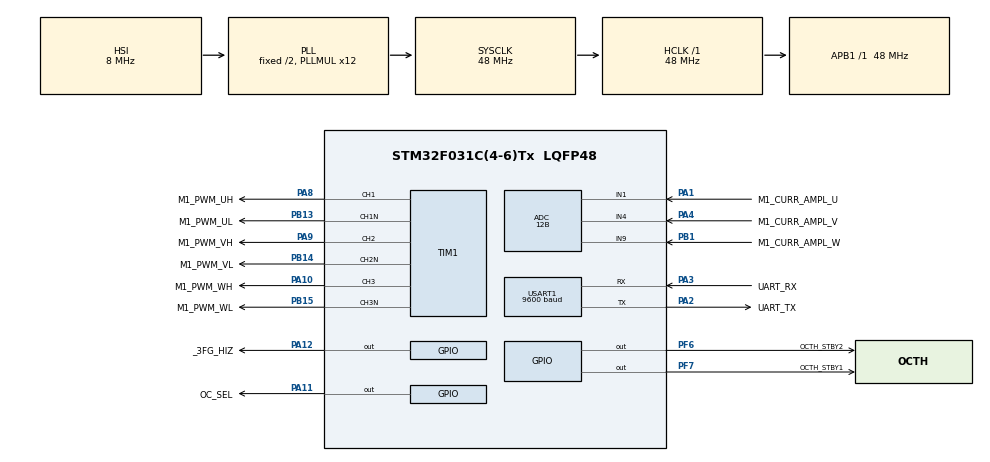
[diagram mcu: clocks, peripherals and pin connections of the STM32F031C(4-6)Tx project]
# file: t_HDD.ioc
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ADC.ClockPrescaler=ADC_CLOCK_ASYNC_DIV1
ADC.ContinuousConvMode=DISABLE
ADC.DMAContinuousRequests=ENABLE
ADC.DataAlign=ADC_DATAALIGN_LEFT
ADC.DiscontinuousConvMode=DISABLE
ADC.EOCSelection=ADC_EOC_SINGLE_CONV
ADC.EnableAnalogWatchDog=false
ADC.ExternalTrigConv=ADC_EXTERNALTRIGCONV_T1_TRGO
ADC.ExternalTrigConvEdge=ADC_EXTERNALTRIGCONVEDGE_RISING
ADC.LowPowerAutoPowerOff=DISABLE
ADC.LowPowerAutoWait=DISABLE
ADC.Overrun=ADC_OVR_DATA_PRESERVED
ADC.Resolution=ADC_RESOLUTION_12B
ADC.SamplingTime=ADC_SAMPLETIME_7CYCLES_5
ADC.ScanConvMode=ADC_SCAN_DIRECTION_FORWARD
Dma.ADC.0.Direction=DMA_PERIPH_TO_MEMORY
Dma.ADC.0.Instance=DMA1_Channel1
Dma.ADC.0.MemDataAlignment=DMA_MDATAALIGN_HALFWORD
Dma.ADC.0.MemInc=DMA_MINC_ENABLE
Dma.ADC.0.Mode=DMA_CIRCULAR
Dma.ADC.0.PeriphDataAlignment=DMA_PDATAALIGN_HALFWORD
Dma.ADC.0.PeriphInc=DMA_PINC_DISABLE
Dma.ADC.0.Priority=DMA_PRIORITY_HIGH
Dma.Request0=ADC
ExtraMW=MotorControl
ExtraMW.MotorControl.Config=MotorControl
ExtraMW.MotorControl.Mode=MotorControl
ExtraMW.MotorControl.Root=MCSDK_v5.1.3/MotorControl
ExtraMW.MotorControl.Template=templates
Mcu.Family=STM32F0
Mcu.Name=STM32F031C(4-6)Tx
Mcu.Package=LQFP48
MotorControl.ADC_1_PERIPH=ADC1
MotorControl.ADC_2_PERIPH=ADC2
MotorControl.ADC_AHBPERIPH=RCC_AHBPeriph_ADC12
MotorControl.ADC_CLOCK_WB_DIV=0
MotorControl.ADC_CLOCK_WB_FREQ=14
MotorControl.ADC_PERIPH=ADC1
MotorControl.ALIGNMENT_ANGLE_DEG=0
MotorControl.ALIGNMENT_DURATION=700
MotorControl.AMPLIFICATION_GAIN=10.00
MotorControl.ANGC={0,0,0,0,0,0,0,0}
MotorControl.BEMF_CONSISTENCY_GAIN=45
MotorControl.BEMF_CONSISTENCY_TOL=45
MotorControl.BKIN1_FILTER=0
MotorControl.BKIN2_FILTER=0
MotorControl.BKIN2_MODE=NONE
MotorControl.BKIN_MODE=NONE
MotorControl.BOARD=CUSTOM
MotorControl.BRKIN2_GPIO_AF=GPIO_AF_2
MotorControl.BRKIN_GPIO_AF=GPIO_AF_2
MotorControl.BUS_VOLTAGE_READING=false
MotorControl.CLOCK_FREQUENCY=CPU_CLK_48_MHZ
MotorControl.CLOCK_SOURCE=INTERNAL
MotorControl.CONSTANT1_D=2136
MotorControl.CONSTANT1_Q=2136
MotorControl.CONSTANT2_QD=315
MotorControl.CORD_BEMF_CONSISTENCY_GAIN=64
MotorControl.CORD_BEMF_CONSISTENCY_TOL=64
MotorControl.CORD_F1=512
MotorControl.CORD_F2=16384
MotorControl.CORD_FIFO_DEPTH_01HZ=64
MotorControl.CORD_FIFO_DEPTH_DPP=64
MotorControl.CORD_GAIN1=-468
MotorControl.CORD_GAIN2=8762
MotorControl.CORD_MAX_ACCEL_DPPP=241
MotorControl.CORD_MEAS_ERRORS_BEFORE_FAULTS=3
MotorControl.CORD_VARIANCE_THRESHOLD=4
MotorControl.CPU_CLK_48_MHZ=true
MotorControl.CTRBDID=0
MotorControl.CURRENT_READING_TOPOLOGY=THREE_SHUNT
MotorControl.CURR_SAMPLING_TIME=7
MotorControl.DAC_EMULATED=false
MotorControl.DAC_FUNCTIONALITY=false
MotorControl.DAC_TIMER_CH1_GPIO_PIN=LL_GPIO_PIN_0
MotorControl.DAC_TIMER_CH1_GPIO_PORT=GPIOA
MotorControl.DAC_TIMER_CH2_GPIO_PIN=LL_GPIO_PIN_0
MotorControl.DAC_TIMER_CH2_GPIO_PORT=GPIOA
MotorControl.DAC_TIMER_REMAPPING=NO_REMAP
MotorControl.DAC_TIMER_SELECTION=TIM3
MotorControl.DC_CURRENT_RS_MEAS=0.50
MotorControl.DEBUG_DAC_CH1=false
MotorControl.DEBUG_DAC_CH2=false
MotorControl.DEFAULT_CONTROL_MODE=STC_SPEED_MODE
MotorControl.DEFAULT_DAC_CHANNEL_1=MC_PROTOCOL_REG_I_A
MotorControl.DEFAULT_DAC_CHANNEL_2=MC_PROTOCOL_REG_I_B
MotorControl.DEFAULT_DAC_MOTOR=0
MotorControl.DEFAULT_FLUX_COMPONENT=0
MotorControl.DEFAULT_TARGET_SPEED_RPM=6000
MotorControl.DEFAULT_TORQUE_COMPONENT=11915
MotorControl.DISSIPATIVE_BRAKE_POLARITY=DOUT_ACTIVE_HIGH
MotorControl.DRIVES_NUMBER_SELECTION=SINGLEDRIVE
MotorControl.EMERGENCY2_STOP_GPIO_PIN=LL_GPIO_PIN_12
MotorControl.EMERGENCY2_STOP_GPIO_PORT=GPIOB
MotorControl.EMERGENCY_STOP_GPIO_PIN=LL_GPIO_PIN_12
MotorControl.EMERGENCY_STOP_GPIO_PORT=GPIOB
MotorControl.ENABLE_SL_ALGO_FROM_PHASE=1
MotorControl.ENCODER_AVAILABLE=false
MotorControl.ENCODER_PPR=1250
MotorControl.ENC_AVERAGING_FIFO_DEPTH=16
MotorControl.ENC_A_GPIO_PIN=LL_GPIO_PIN_6
MotorControl.ENC_A_GPIO_PORT=GPIOA
MotorControl.ENC_B_GPIO_PIN=LL_GPIO_PIN_7
MotorControl.ENC_B_GPIO_PORT=GPIOA
MotorControl.ENC_ICx_FILTER=34
MotorControl.ENC_INVERT_SPEED=false
MotorControl.ENC_MEAS_ERRORS_BEFORE_FAULTS=3
MotorControl.ENC_TIMER_REMAPPING=NO_REMAP_TIM3
MotorControl.ENC_TIMER_SELECTION=ENC_TIM3
MotorControl.EXT_CLOCK_FREQUENCY=INT_RC_OSC
MotorControl.F1=512
MotorControl.F2=16384
MotorControl.FEEDBACK_NET_FILTERING=false
MotorControl.FEED_FORWARD_CURRENT_REG_ENABLING=false
MotorControl.FINAL_I_ALIGNMENT=19858
MotorControl.FLUX_WEAKENING_ENABLING=false
MotorControl.FW_KIDIV=32768
MotorControl.FW_KI_GAIN=5000
MotorControl.FW_KPDIV=32768
MotorControl.FW_KP_GAIN=3000
MotorControl.FW_VOLTAGE_REF=985
MotorControl.GAIN1=-468
MotorControl.GAIN2=8762
MotorControl.H1_GPIO_PIN=LL_GPIO_PIN_0
MotorControl.H1_GPIO_PORT=GPIOA
MotorControl.H2_GPIO_PIN=LL_GPIO_PIN_1
MotorControl.H2_GPIO_PORT=GPIOA
MotorControl.H3_GPIO_PIN=LL_GPIO_PIN_2
MotorControl.H3_GPIO_PORT=GPIOA
MotorControl.HALL_AVERAGING_FIFO_DEPTH=6
MotorControl.HALL_ICx_FILTER=62
MotorControl.HALL_MEAS_ERRORS_BEFORE_FAULTS=3
MotorControl.HALL_PHASE_SHIFT=300
MotorControl.HALL_SENSORS_AVAILABLE=false
MotorControl.HALL_SENSORS_PLACEMENT=DEGREES_120
MotorControl.HALL_TIMER_REMAPPING=NO_REMAP_TIM2
MotorControl.HALL_TIMER_SELECTION=HALL_TIM2
MotorControl.HFI_AMPLITUDE=25
MotorControl.HFI_DC_0_COEFF=0.00146
MotorControl.HFI_DC_1_COEFF=0.002921
MotorControl.HFI_DC_2_COEFF=0.00146
MotorControl.HFI_DC_3_COEFF=1.889033
MotorControl.HFI_DC_4_COEFF=-0.894874
MotorControl.HFI_DEBUG_MODE=false
MotorControl.HFI_FREQUENCY=400
MotorControl.HFI_HIFRAMPLSCAN=25
MotorControl.HFI_HP_ID_0_COEFF=0.855931
MotorControl.HFI_HP_ID_1_COEFF=-1.711861
MotorControl.HFI_HP_ID_2_COEFF=0.855931
MotorControl.HFI_HP_ID_3_COEFF=1.690996
MotorControl.HFI_HP_ID_4_COEFF=-0.732726
MotorControl.HFI_IDH_DELAY=32400
MotorControl.HFI_LOCKFREQ=82
MotorControl.HFI_LP_ID_0_COEFF=0.032106
MotorControl.HFI_LP_ID_1_COEFF=0.064213
MotorControl.HFI_LP_ID_2_COEFF=0.032106
MotorControl.HFI_LP_ID_3_COEFF=1.433067
MotorControl.HFI_LP_ID_4_COEFF=-0.561492
MotorControl.HFI_MAXANGLEDIFF=3640
MotorControl.HFI_MINIMUM_SPEED_RPM=402
MotorControl.HFI_NOTCH_IQD_0_COEFF=0.928286
MotorControl.HFI_NOTCH_IQD_1_COEFF=-1.765705
MotorControl.HFI_NOTCH_IQD_2_COEFF=0.928286
MotorControl.HFI_NOTCH_IQD_3_COEFF=1.765705
MotorControl.HFI_NOTCH_IQD_4_COEFF=-0.856572
MotorControl.HFI_NSDETPOINTSSKIP=10
MotorControl.HFI_NSMAXDETPOINTS=20
MotorControl.HFI_NS_MIN_SAT_DIFF=0
MotorControl.HFI_PID_KIDIV=32768
MotorControl.HFI_PID_KI_DEFAULT=400
MotorControl.HFI_PID_KPDIV=16384
MotorControl.HFI_PID_KP_DEFAULT=800
MotorControl.HFI_PLL_KI_DEFAULT=0.00400
MotorControl.HFI_PLL_KP_DEFAULT=0.00060
MotorControl.HFI_RESTARTTIMESEC=0.1
MotorControl.HFI_RESTART_RPM_TH=(((HFI_STO_RPM_TH)+(STO_HFI_RPM_TH))/2)
MotorControl.HFI_REVERT_DIRECTION=true
MotorControl.HFI_SCANROTATIONSNO=3
MotorControl.HFI_SPD_BUFFER_DEPTH_01HZ=32
MotorControl.HFI_STEPANGLE=3640
MotorControl.HFI_STO_RPM_TH=OBS_MINIMUM_SPEED_RPM
MotorControl.HFI_WAITAFTERNS2=4
MotorControl.HFI_WAITBEFORESN=6
MotorControl.HFI_WAITSYNCH=20
MotorControl.HFI_WAITTRACK=20
MotorControl.HIGH_SIDE_BRAKE_STATE=false
MotorControl.HIGH_SIDE_IDLE_STATE=false
MotorControl.HW_COMPLEMENTED_LOW_SIDE=false
MotorControl.HW_DEAD_TIME_NS=900
MotorControl.HW_OV_CURRENT_PROT_BYPASS=false
MotorControl.ID_DEMAG=-9929
MotorControl.INRUSH_CURRLIMIT_AT_POWER_ON=true
MotorControl.INRUSH_CURRLIMIT_CHANGE_AFTER_MS=1000
MotorControl.INRUSH_CURRLIMIT_ENABLING=false
MotorControl.INRUSH_CURRLIMIT_GPIO_PIN=LL_GPIO_PIN_4
MotorControl.INRUSH_CURRLIMIT_GPIO_PORT=GPIOE
MotorControl.INRUSH_CURR_LIMITER_POLARITY=DOUT_ACTIVE_HIGH
MotorControl.INTERNAL_OVERCURRENTPROTECTION=false
MotorControl.INTERNAL_OVERVOLTAGEPROTECTION=false
MotorControl.INT_RC_OSC=true
MotorControl.IQMAX=9929
MotorControl.LCD_JOYSTICK_FUNCTIONALITY=false
MotorControl.LCD_MODE=LCD_FULL
MotorControl.LDLQ_RATIO=1.000
MotorControl.LOW_SIDE_BRAKE_STATE=false
MotorControl.LOW_SIDE_IDLE_STATE=false
MotorControl.LOW_SIDE_SIGNALS_ENABLING=LS_PWM_TIMER
MotorControl.LS=0.000400
MotorControl.MAX_APPLICATION_SPEED=15000
MotorControl.MAX_MODULATION_85_PER_CENT=true
MotorControl.MAX_MODULATION_INDEX=MAX_MODULATION_85_PER_CENT
MotorControl.MCU=STSPIN32F0
MotorControl.MCU_SUPPLY_VOLTAGE=3.30
MotorControl.MCU_TYPE=STSPIN32F0
MotorControl.MC_WORKBENCH_VERSION=5.1.2.18276
MotorControl.MEAS_ERRORS_BEFORE_FAULTS=3
MotorControl.MIN_APPLICATION_SPEED=0
MotorControl.MOTOR_MAX_SPEED_RPM=15000
MotorControl.MOTOR_TYPE=PMSM
MotorControl.MOTOR_VOLTAGE_CONSTANT=0.6
MotorControl.MTPA_ENABLING=false
MotorControl.NB_CONSECUTIVE_TESTS=2
MotorControl.NOMINAL_BUS_VOLTAGE_V=12
MotorControl.NOMINAL_CURRENT=9929
MotorControl.OBS_MEAS_ERRORS_BEFORE_FAULTS=3
MotorControl.OBS_MINIMUM_SPEED_RPM=580
MotorControl.OCPA_INVERTINGINPUT=COMPX_InvertingInput_VREF
MotorControl.OCPA_INVERTINGINPUT_GPIO_PIN=LL_GPIO_PIN_4
MotorControl.OCPA_INVERTINGINPUT_GPIO_PORT=GPIOA
MotorControl.OCPA_INVERTINGINPUT_MODE=INT_MODE
MotorControl.OCPA_NONINVERTINGINPUT=COMP1_NonInvertingInput_PA1
MotorControl.OCPA_NONINVERTINGINPUT_GPIO_PIN=LL_GPIO_PIN_1
MotorControl.OCPA_NONINVERTINGINPUT_GPIO_PORT=GPIOA
MotorControl.OCPA_OUTPUT=COMP_Output_TIM1BKIN2
MotorControl.OCPA_OUTPUTPOL=COMP_OutputPol_NonInverted
MotorControl.OCPA_OUTPUT_GPIO_AF=GPIO_AF_2
MotorControl.OCPA_OUTPUT_GPIO_PIN=LL_GPIO_PIN_0
MotorControl.OCPA_OUTPUT_GPIO_PORT=GPIOA
MotorControl.OCPA_OUTPUT_MODE=INT_MODE
MotorControl.OCPA_SELECTION=COMP1
MotorControl.OCPB_INVERTINGINPUT=COMPX_InvertingInput_VREF
MotorControl.OCPB_INVERTINGINPUT_GPIO_PIN=LL_GPIO_PIN_4
MotorControl.OCPB_INVERTINGINPUT_GPIO_PORT=GPIOA
MotorControl.OCPB_INVERTINGINPUT_MODE=INT_MODE
MotorControl.OCPB_NONINVERTINGINPUT=COMP2_NonInvertingInput_PA7
MotorControl.OCPB_NONINVERTINGINPUT_GPIO_PIN=LL_GPIO_PIN_7
MotorControl.OCPB_NONINVERTINGINPUT_GPIO_PORT=GPIOA
MotorControl.OCPB_OUTPUT=COMP_Output_TIM1BKIN2
MotorControl.OCPB_OUTPUTPOL=COMP_OutputPol_NonInverted
MotorControl.OCPB_OUTPUT_GPIO_AF=GPIO_AF_2
MotorControl.OCPB_OUTPUT_GPIO_PIN=LL_GPIO_PIN_2
MotorControl.OCPB_OUTPUT_GPIO_PORT=GPIOA
MotorControl.OCPB_OUTPUT_MODE=INT_MODE
MotorControl.OCPB_SELECTION=COMP2
MotorControl.OCPC_INVERTINGINPUT=COMPX_InvertingInput_VREF
MotorControl.OCPC_INVERTINGINPUT_GPIO_PIN=LL_GPIO_PIN_4
MotorControl.OCPC_INVERTINGINPUT_GPIO_PORT=GPIOA
MotorControl.OCPC_INVERTINGINPUT_MODE=INT_MODE
MotorControl.OCPC_NONINVERTINGINPUT=COMP3_NonInvertingInput_PD14
MotorControl.OCPC_NONINVERTINGINPUT_GPIO_PIN=LL_GPIO_PIN_14
MotorControl.OCPC_NONINVERTINGINPUT_GPIO_PORT=GPIOD
MotorControl.OCPC_OUTPUT=COMP_Output_TIM1BKIN2
MotorControl.OCPC_OUTPUTPOL=COMP_OutputPol_NonInverted
MotorControl.OCPC_OUTPUT_GPIO_AF=GPIO_AF_2
MotorControl.OCPC_OUTPUT_GPIO_PIN=LL_GPIO_PIN_8
MotorControl.OCPC_OUTPUT_GPIO_PORT=GPIOC
MotorControl.OCPC_OUTPUT_MODE=INT_MODE
MotorControl.OCPC_SELECTION=COMP3
MotorControl.OCPREF=23830
MotorControl.OCP_COMP_THRESHOLD=0.50
MotorControl.OCP_FILTER=COMP_Mode_HighSpeed
MotorControl.OCP_INVERTINGINPUT=COMPX_InvertingInput_VREF
MotorControl.OCP_INVERTINGINPUT_GPIO_PIN=LL_GPIO_PIN_4
MotorControl.OCP_INVERTINGINPUT_GPIO_PORT=GPIOA
MotorControl.OCP_INVERTINGINPUT_MODE=INT_MODE
MotorControl.OCP_NONINVERTINGINPUT=COMP2_NonInvertingInput_PA7
MotorControl.OCP_NONINVERTINGINPUT_GPIO_PIN=LL_GPIO_PIN_7
MotorControl.OCP_NONINVERTINGINPUT_GPIO_PORT=GPIOA
MotorControl.OCP_OUTPUT=COMP_Output_TIM1BKIN2
MotorControl.OCP_OUTPUTPOL=COMP_OutputPol_NonInverted
MotorControl.OCP_OUTPUT_GPIO_AF=GPIO_AF_2
MotorControl.OCP_OUTPUT_GPIO_PIN=LL_GPIO_PIN_2
MotorControl.OCP_OUTPUT_GPIO_PORT=GPIOA
MotorControl.OCP_OUTPUT_MODE=INT_MODE
MotorControl.OCP_SELECTION=COMP2
MotorControl.OFST={0,0,0,0,0,0,0,0}
MotorControl.ON_OVER_VOLTAGE=TURN_OFF_PWM
MotorControl.OPAMP1_INVERTINGINPUT=OPAMP1_InvertingInput_PGA
MotorControl.OPAMP1_INVERTINGINPUT_GPIO_PIN=LL_GPIO_PIN_3
MotorControl.OPAMP1_INVERTINGINPUT_GPIO_PORT=GPIOA
MotorControl.OPAMP1_INVERTINGINPUT_MODE=INT_MODE
MotorControl.OPAMP1_NONINVERTINGINPUT_PHA=OPAMP1_NonInvertingInput_PA1
MotorControl.OPAMP1_NONINVERTINGINPUT_PHA_GPIO_PIN=LL_GPIO_PIN_1
MotorControl.OPAMP1_NONINVERTINGINPUT_PHA_GPIO_PORT=GPIOA
MotorControl.OPAMP1_NONINVERTINGINPUT_PHB=OPAMP1_NonInvertingInput_PA7
MotorControl.OPAMP1_NONINVERTINGINPUT_PHB_GPIO_PIN=LL_GPIO_PIN_7
MotorControl.OPAMP1_NONINVERTINGINPUT_PHB_GPIO_PORT=GPIOA
MotorControl.OPAMP1_OUT_GPIO_PIN=LL_GPIO_PIN_2
MotorControl.OPAMP1_OUT_GPIO_PORT=GPIOA
MotorControl.OPAMP1_SELECTION=OPAMP1
MotorControl.OPAMP2_INVERTINGINPUT=OPAMP2_InvertingInput_PGA
MotorControl.OPAMP2_INVERTINGINPUT_GPIO_PIN=LL_GPIO_PIN_5
MotorControl.OPAMP2_INVERTINGINPUT_GPIO_PORT=GPIOC
MotorControl.OPAMP2_INVERTINGINPUT_MODE=INT_MODE
MotorControl.OPAMP2_NONINVERTINGINPUT_PHA=OPAMP2_NonInvertingInput_PB14
MotorControl.OPAMP2_NONINVERTINGINPUT_PHA_GPIO_PIN=LL_GPIO_PIN_14
MotorControl.OPAMP2_NONINVERTINGINPUT_PHA_GPIO_PORT=GPIOB
MotorControl.OPAMP2_NONINVERTINGINPUT_PHB=OPAMP2_NonInvertingInput_PA7
MotorControl.OPAMP2_NONINVERTINGINPUT_PHB_GPIO_PIN=LL_GPIO_PIN_7
MotorControl.OPAMP2_NONINVERTINGINPUT_PHB_GPIO_PORT=GPIOA
MotorControl.OPAMP2_NONINVERTINGINPUT_PHC=OPAMP2_NonInvertingInput_PB14
MotorControl.OPAMP2_NONINVERTINGINPUT_PHC_GPIO_PIN=LL_GPIO_PIN_14
MotorControl.OPAMP2_NONINVERTINGINPUT_PHC_GPIO_PORT=GPIOB
MotorControl.OPAMP2_OUT_GPIO_PIN=LL_GPIO_PIN_6
MotorControl.OPAMP2_OUT_GPIO_PORT=GPIOA
MotorControl.OPAMP2_SELECTION=OPAMP2
MotorControl.OPAMP_INVERTINGINPUT=OPAMP1_InvertingInput_PGA
MotorControl.OPAMP_INVERTINGINPUT_GPIO_PIN=LL_GPIO_PIN_3
MotorControl.OPAMP_INVERTINGINPUT_GPIO_PORT=GPIOA
MotorControl.OPAMP_INVERTINGINPUT_MODE=INT_MODE
MotorControl.OPAMP_NONINVERTINGINPUT=OPAMP1_NonInvertingInput_PA7
MotorControl.OPAMP_NONINVERTINGINPUT_GPIO_PIN=LL_GPIO_PIN_7
MotorControl.OPAMP_NONINVERTINGINPUT_GPIO_PORT=GPIOA
MotorControl.OPAMP_OUT_GPIO_PIN=LL_GPIO_PIN_2
MotorControl.OPAMP_OUT_GPIO_PORT=GPIOA
MotorControl.OPAMP_PGACONNECT=OPAMP_PGAConnect_No
MotorControl.OPAMP_PGAGAIN=OPAMP_OPAMP_PGAGain_2
MotorControl.OPAMP_SELECTION=OPAMP1
MotorControl.OPAMP_TYPE_GAIN=INTERNAL
MotorControl.OPEN_LOOP_FOC=false
MotorControl.OPEN_LOOP_K=44
MotorControl.OPEN_LOOP_OFF=4400
MotorControl.OPEN_LOOP_SPEED_RAMP_DURATION_MS=1000
MotorControl.OPEN_LOOP_SPEED_RPM=100
MotorControl.OPEN_LOOP_VF=false
MotorControl.OPEN_LOOP_VOLTAGE_d=6000
MotorControl.OTF_STARTUP=true
MotorControl.OVERCURR_FEEDBACK_POLARITY=EMSTOP_ACTIVE_HIGH
MotorControl.OVERCURR_PROTECTION_HW_DISABLING=DOUT_ACTIVE_HIGH
MotorControl.OVPREF=23830
MotorControl.OVP_FILTER=COMP_Mode_HighSpeed
MotorControl.OVP_INVERTINGINPUT=COMPX_InvertingInput_VREF
MotorControl.OVP_INVERTINGINPUT_GPIO_PIN=LL_GPIO_PIN_4
MotorControl.OVP_INVERTINGINPUT_GPIO_PORT=GPIOA
MotorControl.OVP_INVERTINGINPUT_MODE=INT_MODE
MotorControl.OVP_NONINVERTINGINPUT=COMP7_NonInvertingInput_PA0
MotorControl.OVP_NONINVERTINGINPUT_GPIO_PIN=LL_GPIO_PIN_0
MotorControl.OVP_NONINVERTINGINPUT_GPIO_PORT=GPIOA
MotorControl.OVP_OUTPUT=COMP_Output_TIM1BKIN
MotorControl.OVP_OUTPUTPOL=COMP_OutputPol_NonInverted
MotorControl.OVP_OUTPUT_GPIO_AF=GPIO_AF_2
MotorControl.OVP_OUTPUT_GPIO_PIN=LL_GPIO_PIN_2
MotorControl.OVP_OUTPUT_GPIO_PORT=GPIOC
MotorControl.OVP_OUTPUT_MODE=INT_MODE
MotorControl.OVP_SELECTION=COMP7
MotorControl.OV_CURR_BYPASS_GPIO_PIN=LL_GPIO_PIN_5
MotorControl.OV_CURR_BYPASS_GPIO_PORT=GPIOE
MotorControl.OV_TEMPERATURE_HYSTERESIS_C=10
MotorControl.OV_TEMPERATURE_PROT_ENABLING=false
MotorControl.OV_TEMPERATURE_THRESHOLD_C=70
MotorControl.OV_VOLTAGE_PROT_ENABLING=false
MotorControl.OV_VOLTAGE_THRESHOLD_V=16
MotorControl.PHASE1_DURATION=1000
MotorControl.PHASE1_FINAL_CURRENT=0
MotorControl.PHASE1_FINAL_SPEED_RPM=0
MotorControl.PHASE2_DURATION=1000
MotorControl.PHASE2_FINAL_CURRENT=0
MotorControl.PHASE2_FINAL_SPEED_RPM=0
MotorControl.PHASE3_DURATION=500
MotorControl.PHASE3_FINAL_CURRENT=9929
MotorControl.PHASE3_FINAL_SPEED_RPM=0
MotorControl.PHASE4_DURATION=1000
MotorControl.PHASE4_FINAL_CURRENT=9929
MotorControl.PHASE4_FINAL_SPEED_RPM=6000
MotorControl.PHASE5_DURATION=0
MotorControl.PHASE5_FINAL_CURRENT=9929
MotorControl.PHASE5_FINAL_SPEED_RPM=6000
MotorControl.PHASE_CURRENTS_ADC=ADC1_2
MotorControl.PHASE_CURRENTS_CHANNEL=ADC_CHANNEL_9
MotorControl.PHASE_CURRENTS_GPIO_PIN=LL_GPIO_PIN_0
MotorControl.PHASE_CURRENTS_GPIO_PORT=GPIOA
MotorControl.PHASE_UH_GPIO_AF=GPIO_AF_2
MotorControl.PHASE_UH_GPIO_PIN=LL_GPIO_PIN_8
MotorControl.PHASE_UH_GPIO_PORT=GPIOA
MotorControl.PHASE_UH_POLARITY=H_ACTIVE_HIGH
MotorControl.PHASE_UL_GPIO_AF=GPIO_AF_2
MotorControl.PHASE_UL_GPIO_PIN=LL_GPIO_PIN_13
MotorControl.PHASE_UL_GPIO_PORT=GPIOB
MotorControl.PHASE_UL_POLARITY=L_ACTIVE_HIGH
MotorControl.PHASE_U_CURR_ADC=ADC1
MotorControl.PHASE_U_CURR_CHANNEL=ADC_CHANNEL_1
MotorControl.PHASE_U_GPIO_PIN=LL_GPIO_PIN_1
MotorControl.PHASE_U_GPIO_PORT=GPIOA
MotorControl.PHASE_VH_GPIO_AF=GPIO_AF_2
MotorControl.PHASE_VH_GPIO_PIN=LL_GPIO_PIN_9
MotorControl.PHASE_VH_GPIO_PORT=GPIOA
MotorControl.PHASE_VH_POLARITY=H_ACTIVE_HIGH
MotorControl.PHASE_VL_GPIO_AF=GPIO_AF_2
MotorControl.PHASE_VL_GPIO_PIN=LL_GPIO_PIN_14
MotorControl.PHASE_VL_GPIO_PORT=GPIOB
MotorControl.PHASE_VL_POLARITY=L_ACTIVE_HIGH
MotorControl.PHASE_V_CURR_ADC=ADC1
MotorControl.PHASE_V_CURR_CHANNEL=ADC_CHANNEL_4
MotorControl.PHASE_V_GPIO_PIN=LL_GPIO_PIN_4
MotorControl.PHASE_V_GPIO_PORT=GPIOA
MotorControl.PHASE_WH_GPIO_AF=GPIO_AF_2
MotorControl.PHASE_WH_GPIO_PIN=LL_GPIO_PIN_10
MotorControl.PHASE_WH_GPIO_PORT=GPIOA
MotorControl.PHASE_WH_POLARITY=H_ACTIVE_HIGH
MotorControl.PHASE_WL_GPIO_AF=GPIO_AF_2
MotorControl.PHASE_WL_GPIO_PIN=LL_GPIO_PIN_15
MotorControl.PHASE_WL_GPIO_PORT=GPIOB
MotorControl.PHASE_WL_POLARITY=L_ACTIVE_HIGH
MotorControl.PHASE_W_CURR_ADC=ADC1
MotorControl.PHASE_W_CURR_CHANNEL=ADC_CHANNEL_9
MotorControl.PHASE_W_GPIO_PIN=LL_GPIO_PIN_1
MotorControl.PHASE_W_GPIO_PORT=GPIOB
MotorControl.PID_FLUX_KD_DEFAULT=100
MotorControl.PID_FLUX_KI_DEFAULT=141
MotorControl.PID_FLUX_KP_DEFAULT=180
MotorControl.PID_SPEED_KD_DEFAULT=0
MotorControl.PID_SPEED_KI_DEFAULT=10
MotorControl.PID_SPEED_KP_DEFAULT=300
MotorControl.PID_TORQUE_KD_DEFAULT=100
MotorControl.PID_TORQUE_KI_DEFAULT=141
MotorControl.PID_TORQUE_KP_DEFAULT=180
MotorControl.PLL_KI_GAIN=200
MotorControl.PLL_KP_GAIN=600
MotorControl.POLE_PAIR_NUM=4
MotorControl.PWBDID=0
MotorControl.PWM_FREQUENCY=16000
MotorControl.PWM_TIMER_REMAPPING=PWM_NO_REMAP
MotorControl.PWM_TIMER_SELECTION=PWM_TIM1
MotorControl.REGCONVADC=ADC1
MotorControl.REGULATION_EXECUTION_RATE=2
MotorControl.RS=2.50
MotorControl.RSHUNT=0.100
MotorControl.R_BRAKE_GPIO_PIN=LL_GPIO_PIN_5
MotorControl.R_BRAKE_GPIO_PORT=GPIOE
MotorControl.R_BRAKE_SWITCH_OFF_THRES_V=13
MotorControl.SEGDIV=0
MotorControl.SERIAL_COMMUNICATION=true
MotorControl.SERIAL_COM_CHANNEL1=MC_PROTOCOL_REG_I_A
MotorControl.SERIAL_COM_CHANNEL2=MC_PROTOCOL_REG_I_A
MotorControl.SERIAL_COM_MODE=COM_BIDIRECTIONAL
MotorControl.SERIAL_COM_MOTOR=0
MotorControl.SHARED_SIGNAL_ENABLE=false
MotorControl.SINGLEDRIVE=true
MotorControl.SPD_DIFFERENTIAL_TERM_ENABLING=false
MotorControl.SPEED_BAND_LOWER_LIMIT=15
MotorControl.SPEED_BAND_UPPER_LIMIT=17
MotorControl.SPEED_LOOP_FREQUENCY_HZ=1000
MotorControl.SPEED_SENSOR_SELECTION=STATE_OBSERVER_PLL
MotorControl.SP_KDDIV=16
MotorControl.SP_KIDIV=128
MotorControl.SP_KPDIV=1
MotorControl.STARTING_ANGLE_DEG=90
MotorControl.START_STOP_BTN=false
MotorControl.START_STOP_GPIO_PIN=LL_GPIO_PIN_6
MotorControl.START_STOP_GPIO_PORT=GPIOE
MotorControl.START_STOP_POLARITY=DIN_ACTIVE_LOW
MotorControl.STATE_OBSERVER_PLL=true
MotorControl.STO_FIFO_DEPTH_01HZ=32
MotorControl.STO_FIFO_DEPTH_DPP=32
MotorControl.STO_HFI_RPM_TH=460
MotorControl.STSPIN32F0=true
MotorControl.SW_DEADTIME_NS=800
MotorControl.SW_OV_CURRENT_PROT_ENABLING=false
MotorControl.T0_C=25
MotorControl.TEMPERATURE_READING=false
MotorControl.TEMP_ADC_SAMPLING_TIME=1
MotorControl.TEMP_FDBK_ADC=ADC1
MotorControl.TEMP_FDBK_CHANNEL=ADC_CHANNEL_5
MotorControl.TEMP_FDBK_GPIO_PIN=LL_GPIO_PIN_5
MotorControl.TEMP_FDBK_GPIO_PORT=GPIOA
MotorControl.TFDIFFERENTIAL_TERM_ENABLING=false
MotorControl.TF_KDDIV=8192
MotorControl.TF_KIDIV=16384
MotorControl.TF_KPDIV=16384
MotorControl.THREE_SHUNT=true
MotorControl.TNOISE_NS=2550
MotorControl.TRANSITION_DURATION=0
MotorControl.TRISE_NS=2550
MotorControl.T_MAX=70
MotorControl.UD_VOLTAGE_THRESHOLD_V=8
MotorControl.USART_REMAPPING=NO_REMAP_USART1
MotorControl.USART_RX_GPIO_PIN=LL_GPIO_PIN_3
MotorControl.USART_RX_GPIO_PORT=GPIOA
MotorControl.USART_SELECTION=USE_USART1
MotorControl.USART_SPEED=9600
MotorControl.USART_TX_GPIO_PIN=LL_GPIO_PIN_2
MotorControl.USART_TX_GPIO_PORT=GPIOA
MotorControl.USE_INTERNAL_OPAMP=false
MotorControl.UV_VOLTAGE_PROT_ENABLING=false
MotorControl.V0_V=0.290
MotorControl.VARIANCE_THRESHOLD=0.1
MotorControl.VBUS_ADC=ADC1
MotorControl.VBUS_ADC_SAMPLING_TIME=61
MotorControl.VBUS_CHANNEL=ADC_CHANNEL_1
MotorControl.VBUS_GPIO_PIN=LL_GPIO_PIN_1
MotorControl.VBUS_GPIO_PORT=GPIOA
MotorControl.VBUS_PARTITIONING_FACTOR=0.0086
MotorControl.dV_dT=0.025
NVIC.DMA1_Channel1_IRQn=true\:0\:0\:true\:true\:false\:3\:true
NVIC.TIM1_BRK_UP_TRG_COM_IRQn=true\:0\:0\:false\:true\:false\:1\:true
NVIC.USART1_IRQn=true\:3\:0\:true\:true\:false\:4\:true
PA1.GPIO_Label=M1_CURR_AMPL_U
PA1.Mode=IN1
PA1.Signal=ADC_IN1
PA10.GPIO_Label=M1_PWM_WH
PA10.GPIO_PuPd=GPIO_PULLDOWN
PA10.GPIO_Speed=GPIO_SPEED_FREQ_HIGH
PA10.Signal=S_TIM1_CH3
PA11.GPIO_Label=OC_SEL
PA11.GPIO_PuPd=GPIO_PULLDOWN
PA11.PinState=GPIO_PIN_SET
PA11.Signal=GPIO_Output
PA12.GPIO_Label=_3FG_HIZ
PA12.GPIO_PuPd=GPIO_PULLDOWN
PA12.Signal=GPIO_Output
PA2.GPIO_Label=UART_TX
PA2.GPIO_Mode=GPIO_MODE_AF_PP
PA2.GPIO_PuPd=GPIO_NOPULL
PA2.GPIO_Speed=GPIO_SPEED_FREQ_LOW
PA2.Mode=Asynchronous
PA2.Signal=USART1_TX
PA3.GPIO_Label=UART_RX
PA3.GPIO_Mode=GPIO_MODE_AF_PP
PA3.GPIO_PuPd=GPIO_NOPULL
PA3.GPIO_Speed=GPIO_SPEED_FREQ_LOW
PA3.Mode=Asynchronous
PA3.Signal=USART1_RX
PA4.GPIO_Label=M1_CURR_AMPL_V
PA4.Mode=IN4
PA4.Signal=ADC_IN4
PA8.GPIO_Label=M1_PWM_UH
PA8.GPIO_PuPd=GPIO_PULLDOWN
PA8.GPIO_Speed=GPIO_SPEED_FREQ_HIGH
PA8.Signal=S_TIM1_CH1
PA9.GPIO_Label=M1_PWM_VH
PA9.GPIO_PuPd=GPIO_PULLDOWN
PA9.GPIO_Speed=GPIO_SPEED_FREQ_HIGH
PA9.Signal=S_TIM1_CH2
PB1.GPIO_Label=M1_CURR_AMPL_W
PB1.Mode=IN9
PB1.Signal=ADC_IN9
PB13.GPIO_Label=M1_PWM_UL
PB13.GPIO_PuPd=GPIO_PULLDOWN
PB13.GPIO_Speed=GPIO_SPEED_FREQ_HIGH
PB13.Mode=PWM Generation1 CH1 CH1N
PB13.Signal=TIM1_CH1N
PB14.GPIO_Label=M1_PWM_VL
PB14.GPIO_PuPd=GPIO_PULLDOWN
PB14.GPIO_Speed=GPIO_SPEED_FREQ_HIGH
PB14.Mode=PWM Generation2 CH2 CH2N
PB14.Signal=TIM1_CH2N
PB15.GPIO_Label=M1_PWM_WL
PB15.GPIO_PuPd=GPIO_PULLDOWN
PB15.GPIO_Speed=GPIO_SPEED_FREQ_HIGH
PB15.Mode=PWM Generation3 CH3 CH3N
PB15.Signal=TIM1_CH3N
PF6.GPIO_Label=OCTH_STBY2
PF6.GPIO_PuPd=GPIO_PULLDOWN
PF6.PinState=GPIO_PIN_SET
PF6.Signal=GPIO_Output
PF7.GPIO_Label=OCTH_STBY1
PF7.GPIO_PuPd=GPIO_PULLDOWN
PF7.PinState=GPIO_PIN_SET
PF7.Signal=GPIO_Output
ProjectManager.HeapSize=0x200
ProjectManager.StackSize=0x400
ProjectManager.TargetToolchain=MDK-ARM V5
RCC.AHBFreq_Value=48000000
RCC.APB1Freq_Value=48000000
RCC.APB1TimFreq_Value=48000000
RCC.EnbaleCSS=true
RCC.HCLKFreq_Value=48000000
RCC.PLLMUL=RCC_PLL_MUL12
RCC.SYSCLKFreq_VALUE=48000000
RCC.SYSCLKSource=RCC_SYSCLKSOURCE_PLLCLK
SH.S_TIM1_CH1.0=TIM1_CH1,PWM Generation1 CH1 CH1N
SH.S_TIM1_CH2.0=TIM1_CH2,PWM Generation2 CH2 CH2N
SH.S_TIM1_CH3.0=TIM1_CH3,PWM Generation3 CH3 CH3N
TIM1.AutoReloadPreload=TIM_AUTORELOAD_PRELOAD_DISABLE
TIM1.AutomaticOutput=TIM_AUTOMATICOUTPUT_DISABLE
TIM1.BreakPolarity=TIM_BREAKPOLARITY_HIGH
TIM1.BreakState=TIM_BREAK_ENABLE
TIM1.Channel-PWM\ Generation1\ CH1\ CH1N=TIM_CHANNEL_1
TIM1.Channel-PWM\ Generation2\ CH2\ CH2N=TIM_CHANNEL_2
TIM1.Channel-PWM\ Generation3\ CH3\ CH3N=TIM_CHANNEL_3
TIM1.Channel-PWM\ Generation4\ No\ Output=TIM_CHANNEL_4
TIM1.ClockDivision=TIM_CLOCKDIVISION_DIV2
TIM1.CounterMode=TIM_COUNTERMODE_CENTERALIGNED1
TIM1.DeadTime=((DEAD_TIME_COUNTS) / 2)
TIM1.LockLevel=TIM_LOCKLEVEL_1
TIM1.OCIdleState_1=TIM_OCIDLESTATE_RESET
TIM1.OCIdleState_2=TIM_OCIDLESTATE_RESET
TIM1.OCIdleState_3=TIM_OCIDLESTATE_RESET
TIM1.OCIdleState_4=TIM_OCIDLESTATE_RESET
TIM1.OCMode_PWM-PWM\ Generation1\ CH1\ CH1N=TIM_OCMODE_PWM1
TIM1.OCMode_PWM-PWM\ Generation2\ CH2\ CH2N=TIM_OCMODE_PWM1
TIM1.OCMode_PWM-PWM\ Generation3\ CH3\ CH3N=TIM_OCMODE_PWM1
TIM1.OCMode_PWM-PWM\ Generation4\ No\ Output=TIM_OCMODE_PWM2
TIM1.OCNIdleState_1=TIM_OCNIDLESTATE_RESET
TIM1.OCNIdleState_2=TIM_OCNIDLESTATE_RESET
TIM1.OCNIdleState_3=TIM_OCNIDLESTATE_RESET
TIM1.OCNPolarity_1=TIM_OCNPOLARITY_HIGH
TIM1.OCNPolarity_2=TIM_OCNPOLARITY_HIGH
TIM1.OCNPolarity_3=TIM_OCNPOLARITY_HIGH
TIM1.OCPolarity_1=TIM_OCPOLARITY_HIGH
TIM1.OCPolarity_2=TIM_OCPOLARITY_HIGH
TIM1.OCPolarity_3=TIM_OCPOLARITY_HIGH
TIM1.OCPolarity_4=TIM_OCPOLARITY_HIGH
TIM1.OffStateIDLEMode=TIM_OSSI_ENABLE
TIM1.OffStateRunMode=TIM_OSSR_ENABLE
TIM1.Period=((PWM_PERIOD_CYCLES) / 2)
TIM1.Prescaler=((TIM_CLOCK_DIVIDER) - 1)
TIM1.Pulse-PWM\ Generation1\ CH1=((PWM_PERIOD_CYCLES) / 4)
TIM1.Pulse-PWM\ Generation2\ CH2=((PWM_PERIOD_CYCLES) / 4)
TIM1.Pulse-PWM\ Generation3\ CH3=((PWM_PERIOD_CYCLES) / 4)
TIM1.Pulse-PWM\ Generation4\ No\ Output=(((PWM_PERIOD_CYCLES) / 2) - (HTMIN))
TIM1.RepetitionCounter=(REP_COUNTER)
TIM1.TIM_MasterOutputTrigger=TIM_TRGO_OC4REF
TIM1.TIM_MasterSlaveMode=TIM_MASTERSLAVEMODE_DISABLE
USART1.BaudRate=9600
USART1.VirtualMode-Asynchronous=VM_ASYNC
USART1.WordLength=WORDLENGTH_8B
VP_MotorControl_MC_ENABLED.Mode=Enabled
VP_TIM1_VS_no_output4.Mode=PWM Generation4 No Output
board=custom

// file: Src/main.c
/**
  ******************************************************************************
  * @file           : main.c
  * @brief          : Main program body
  ******************************************************************************
  * This notice applies to any and all portions of this file
  * that are not between comment pairs USER CODE BEGIN and
  * USER CODE END. Other portions of this file, whether
  * inserted by the user or by software development tools
  * are owned by their respective copyright owners.
  *
  * Copyright (c) 2018 STMicroelectronics International N.V.
  * All rights reserved.
  *
  * Redistribution and use in source and binary forms, with or without
  * modification, are permitted, provided that the following conditions are met:
  *
  * 1. Redistribution of source code must retain the above copyright notice,
  *    this list of conditions and the following disclaimer.
  * 2. Redistributions in binary form must reproduce the above copyright notice,
  *    this list of conditions and the following disclaimer in the documentation
  *    and/or other materials provided with the distribution.
  * 3. Neither the name of STMicroelectronics nor the names of other
  *    contributors to this software may be used to endorse or promote products
  *    derived from this software without specific written permission.
  * 4. This software, including modifications and/or derivative works of this
  *    software, must execute solely and exclusively on microcontroller or
  *    microprocessor devices manufactured by or for STMicroelectronics.
  * 5. Redistribution and use of this software other than as permitted under
  *    this license is void and will automatically terminate your rights under
  *    this license.
  *
  * THIS SOFTWARE IS PROVIDED BY STMICROELECTRONICS AND CONTRIBUTORS "AS IS"
  * AND ANY EXPRESS, IMPLIED OR STATUTORY WARRANTIES, INCLUDING, BUT NOT
  * LIMITED TO, THE IMPLIED WARRANTIES OF MERCHANTABILITY, FITNESS FOR A
  * PARTICULAR PURPOSE AND NON-INFRINGEMENT OF THIRD PARTY INTELLECTUAL PROPERTY
  * RIGHTS ARE DISCLAIMED TO THE FULLEST EXTENT PERMITTED BY LAW. IN NO EVENT
  * SHALL STMICROELECTRONICS OR CONTRIBUTORS BE LIABLE FOR ANY DIRECT, INDIRECT,
  * INCIDENTAL, SPECIAL, EXEMPLARY, OR CONSEQUENTIAL DAMAGES (INCLUDING, BUT NOT
  * LIMITED TO, PROCUREMENT OF SUBSTITUTE GOODS OR SERVICES; LOSS OF USE, DATA,
  * OR PROFITS; OR BUSINESS INTERRUPTION) HOWEVER CAUSED AND ON ANY THEORY OF
  * LIABILITY, WHETHER IN CONTRACT, STRICT LIABILITY, OR TORT (INCLUDING
  * NEGLIGENCE OR OTHERWISE) ARISING IN ANY WAY OUT OF THE USE OF THIS SOFTWARE,
  * EVEN IF ADVISED OF THE POSSIBILITY OF SUCH DAMAGE.
  *
  ******************************************************************************
  */
#include "main.h"
#include "stm32f0xx_hal.h"
#include "motorcontrol.h"

ADC_HandleTypeDef hadc;
DMA_HandleTypeDef hdma_adc;

TIM_HandleTypeDef htim1;

UART_HandleTypeDef huart1;

/* USER CODE BEGIN PV */
/* Private variables ---------------------------------------------------------*/

/* USER CODE END PV */

void SystemClock_Config(void);
static void MX_GPIO_Init(void);
static void MX_DMA_Init(void);
static void MX_ADC_Init(void);
static void MX_TIM1_Init(void);
static void MX_USART1_UART_Init(void);
static void MX_NVIC_Init(void);

void HAL_TIM_MspPostInit(TIM_HandleTypeDef *htim);

/* USER CODE BEGIN PFP */
/* Private function prototypes -----------------------------------------------*/

/* USER CODE END PFP */

/* USER CODE BEGIN 0 */
int a_speed;
int a_iqr, a_iq, a_idr, a_id, a_ia, a_ib;
/* USER CODE END 0 */

int main(void)
{
  /* USER CODE BEGIN 1 */
	Curr_Components iqdr, iqd, iab;

  /* USER CODE END 1 */

  /* MCU Configuration----------------------------------------------------------*/

  /* Reset of all peripherals, Initializes the Flash interface and the Systick. */
  HAL_Init();

  /* Configure the system clock */
  SystemClock_Config();

  /* Initialize all configured peripherals */
  MX_GPIO_Init();
  MX_DMA_Init();
  MX_ADC_Init();
  MX_TIM1_Init();
  MX_USART1_UART_Init();
  MX_MotorControl_Init();

  /* Initialize interrupts */
  MX_NVIC_Init();

  /* Infinite loop */
  /* USER CODE BEGIN WHILE */
  while (1)
  {
		a_speed = MC_GetMecSpeedAverageMotor1();

		iqdr = MC_GetIqdrefMotor1();
		iqd = MC_GetIqdMotor1();
		iab = MC_GetIabMotor1();

		a_iqr = iqdr.qI_Component1;
		a_idr = iqdr.qI_Component2;

		a_iq = iqd.qI_Component1;
		a_id = iqd.qI_Component2;

		a_ia = iab.qI_Component1;
		a_ib = iab.qI_Component2;

		HAL_Delay(10);

  /* USER CODE END WHILE */

  }

}

void SystemClock_Config(void)
{

  RCC_OscInitTypeDef RCC_OscInitStruct;
  RCC_ClkInitTypeDef RCC_ClkInitStruct;
  RCC_PeriphCLKInitTypeDef PeriphClkInit;

    /**Initializes the CPU, AHB and APB busses clocks
    */
  RCC_OscInitStruct.OscillatorType = RCC_OSCILLATORTYPE_HSI|RCC_OSCILLATORTYPE_HSI14;
  RCC_OscInitStruct.HSIState = RCC_HSI_ON;
  RCC_OscInitStruct.HSI14State = RCC_HSI14_ON;
  RCC_OscInitStruct.HSICalibrationValue = 16;
  RCC_OscInitStruct.HSI14CalibrationValue = 16;
  RCC_OscInitStruct.PLL.PLLState = RCC_PLL_ON;
  RCC_OscInitStruct.PLL.PLLSource = RCC_PLLSOURCE_HSI;
  RCC_OscInitStruct.PLL.PLLMUL = RCC_PLL_MUL12;
  RCC_OscInitStruct.PLL.PREDIV = RCC_PREDIV_DIV1;
  if (HAL_RCC_OscConfig(&RCC_OscInitStruct) != HAL_OK)
  {
    _Error_Handler(__FILE__, __LINE__);
  }

    /**Initializes the CPU, AHB and APB busses clocks
    */
  RCC_ClkInitStruct.ClockType = RCC_CLOCKTYPE_HCLK|RCC_CLOCKTYPE_SYSCLK
                              |RCC_CLOCKTYPE_PCLK1;
  RCC_ClkInitStruct.SYSCLKSource = RCC_SYSCLKSOURCE_PLLCLK;
  RCC_ClkInitStruct.AHBCLKDivider = RCC_SYSCLK_DIV1;
  RCC_ClkInitStruct.APB1CLKDivider = RCC_HCLK_DIV1;

  if (HAL_RCC_ClockConfig(&RCC_ClkInitStruct, FLASH_LATENCY_1) != HAL_OK)
  {
    _Error_Handler(__FILE__, __LINE__);
  }

  PeriphClkInit.PeriphClockSelection = RCC_PERIPHCLK_USART1;
  PeriphClkInit.Usart1ClockSelection = RCC_USART1CLKSOURCE_PCLK1;
  if (HAL_RCCEx_PeriphCLKConfig(&PeriphClkInit) != HAL_OK)
  {
    _Error_Handler(__FILE__, __LINE__);
  }

    /**Enables the Clock Security System
    */
  HAL_RCC_EnableCSS();

    /**Configure the Systick interrupt time
    */
  HAL_SYSTICK_Config(HAL_RCC_GetHCLKFreq()/1000);

    /**Configure the Systick
    */
  HAL_SYSTICK_CLKSourceConfig(SYSTICK_CLKSOURCE_HCLK);

  /* SysTick_IRQn interrupt configuration */
  HAL_NVIC_SetPriority(SysTick_IRQn, 3, 0);
}

/**
  * @brief NVIC Configuration.
  * @retval None
  */
static void MX_NVIC_Init(void)
{
  /* TIM1_BRK_UP_TRG_COM_IRQn interrupt configuration */
  HAL_NVIC_SetPriority(TIM1_BRK_UP_TRG_COM_IRQn, 0, 0);
  HAL_NVIC_EnableIRQ(TIM1_BRK_UP_TRG_COM_IRQn);
  /* DMA1_Channel1_IRQn interrupt configuration */
  HAL_NVIC_SetPriority(DMA1_Channel1_IRQn, 0, 0);
  HAL_NVIC_EnableIRQ(DMA1_Channel1_IRQn);
  /* USART1_IRQn interrupt configuration */
  HAL_NVIC_SetPriority(USART1_IRQn, 3, 0);
  HAL_NVIC_EnableIRQ(USART1_IRQn);
}

/* ADC init function */
static void MX_ADC_Init(void)
{

  ADC_ChannelConfTypeDef sConfig;

    /**Configure the global features of the ADC (Clock, Resolution, Data Alignment and number of conversion)
    */
  hadc.Instance = ADC1;
  hadc.Init.ClockPrescaler = ADC_CLOCK_ASYNC_DIV1;
  hadc.Init.Resolution = ADC_RESOLUTION_12B;
  hadc.Init.DataAlign = ADC_DATAALIGN_LEFT;
  hadc.Init.ScanConvMode = ADC_SCAN_DIRECTION_FORWARD;
  hadc.Init.EOCSelection = ADC_EOC_SINGLE_CONV;
  hadc.Init.LowPowerAutoWait = DISABLE;
  hadc.Init.LowPowerAutoPowerOff = DISABLE;
  hadc.Init.ContinuousConvMode = DISABLE;
  hadc.Init.DiscontinuousConvMode = DISABLE;
  hadc.Init.ExternalTrigConv = ADC_EXTERNALTRIGCONV_T1_TRGO;
  hadc.Init.ExternalTrigConvEdge = ADC_EXTERNALTRIGCONVEDGE_RISING;
  hadc.Init.DMAContinuousRequests = ENABLE;
  hadc.Init.Overrun = ADC_OVR_DATA_PRESERVED;
  if (HAL_ADC_Init(&hadc) != HAL_OK)
  {
    _Error_Handler(__FILE__, __LINE__);
  }

    /**Configure for the selected ADC regular channel to be converted.
    */
  sConfig.Channel = ADC_CHANNEL_1;
  sConfig.Rank = ADC_RANK_CHANNEL_NUMBER;
  sConfig.SamplingTime = ADC_SAMPLETIME_7CYCLES_5;
  if (HAL_ADC_ConfigChannel(&hadc, &sConfig) != HAL_OK)
  {
    _Error_Handler(__FILE__, __LINE__);
  }

    /**Configure for the selected ADC regular channel to be converted.
    */
  sConfig.Channel = ADC_CHANNEL_4;
  if (HAL_ADC_ConfigChannel(&hadc, &sConfig) != HAL_OK)
  {
    _Error_Handler(__FILE__, __LINE__);
  }

    /**Configure for the selected ADC regular channel to be converted.
    */
  sConfig.Channel = ADC_CHANNEL_9;
  if (HAL_ADC_ConfigChannel(&hadc, &sConfig) != HAL_OK)
  {
    _Error_Handler(__FILE__, __LINE__);
  }

}

/* TIM1 init function */
static void MX_TIM1_Init(void)
{

  TIM_MasterConfigTypeDef sMasterConfig;
  TIM_OC_InitTypeDef sConfigOC;
  TIM_BreakDeadTimeConfigTypeDef sBreakDeadTimeConfig;

  htim1.Instance = TIM1;
  htim1.Init.Prescaler = ((TIM_CLOCK_DIVIDER) - 1);
  htim1.Init.CounterMode = TIM_COUNTERMODE_CENTERALIGNED1;
  htim1.Init.Period = ((PWM_PERIOD_CYCLES) / 2);
  htim1.Init.ClockDivision = TIM_CLOCKDIVISION_DIV2;
  htim1.Init.RepetitionCounter = (REP_COUNTER);
  htim1.Init.AutoReloadPreload = TIM_AUTORELOAD_PRELOAD_DISABLE;
  if (HAL_TIM_PWM_Init(&htim1) != HAL_OK)
  {
    _Error_Handler(__FILE__, __LINE__);
  }

  sMasterConfig.MasterOutputTrigger = TIM_TRGO_OC4REF;
  sMasterConfig.MasterSlaveMode = TIM_MASTERSLAVEMODE_DISABLE;
  if (HAL_TIMEx_MasterConfigSynchronization(&htim1, &sMasterConfig) != HAL_OK)
  {
    _Error_Handler(__FILE__, __LINE__);
  }

  sConfigOC.OCMode = TIM_OCMODE_PWM1;
  sConfigOC.Pulse = 0;
  sConfigOC.OCPolarity = TIM_OCPOLARITY_HIGH;
  sConfigOC.OCNPolarity = TIM_OCNPOLARITY_HIGH;
  sConfigOC.OCFastMode = TIM_OCFAST_DISABLE;
  sConfigOC.OCIdleState = TIM_OCIDLESTATE_RESET;
  sConfigOC.OCNIdleState = TIM_OCNIDLESTATE_RESET;
  if (HAL_TIM_PWM_ConfigChannel(&htim1, &sConfigOC, TIM_CHANNEL_1) != HAL_OK)
  {
    _Error_Handler(__FILE__, __LINE__);
  }

  if (HAL_TIM_PWM_ConfigChannel(&htim1, &sConfigOC, TIM_CHANNEL_2) != HAL_OK)
  {
    _Error_Handler(__FILE__, __LINE__);
  }

  if (HAL_TIM_PWM_ConfigChannel(&htim1, &sConfigOC, TIM_CHANNEL_3) != HAL_OK)
  {
    _Error_Handler(__FILE__, __LINE__);
  }

  sConfigOC.OCMode = TIM_OCMODE_PWM2;
  sConfigOC.Pulse = (((PWM_PERIOD_CYCLES) / 2) - (HTMIN));
  if (HAL_TIM_PWM_ConfigChannel(&htim1, &sConfigOC, TIM_CHANNEL_4) != HAL_OK)
  {
    _Error_Handler(__FILE__, __LINE__);
  }

  sBreakDeadTimeConfig.OffStateRunMode = TIM_OSSR_ENABLE;
  sBreakDeadTimeConfig.OffStateIDLEMode = TIM_OSSI_ENABLE;
  sBreakDeadTimeConfig.LockLevel = TIM_LOCKLEVEL_1;
  sBreakDeadTimeConfig.DeadTime = ((DEAD_TIME_COUNTS) / 2);
  sBreakDeadTimeConfig.BreakState = TIM_BREAK_ENABLE;
  sBreakDeadTimeConfig.BreakPolarity = TIM_BREAKPOLARITY_HIGH;
  sBreakDeadTimeConfig.AutomaticOutput = TIM_AUTOMATICOUTPUT_DISABLE;
  if (HAL_TIMEx_ConfigBreakDeadTime(&htim1, &sBreakDeadTimeConfig) != HAL_OK)
  {
    _Error_Handler(__FILE__, __LINE__);
  }

  HAL_TIM_MspPostInit(&htim1);

}

/* USART1 init function */
static void MX_USART1_UART_Init(void)
{

  huart1.Instance = USART1;
  huart1.Init.BaudRate = 9600;
  huart1.Init.WordLength = UART_WORDLENGTH_8B;
  huart1.Init.StopBits = UART_STOPBITS_1;
  huart1.Init.Parity = UART_PARITY_NONE;
  huart1.Init.Mode = UART_MODE_TX_RX;
  huart1.Init.HwFlowCtl = UART_HWCONTROL_NONE;
  huart1.Init.OverSampling = UART_OVERSAMPLING_16;
  huart1.Init.OneBitSampling = UART_ONE_BIT_SAMPLE_DISABLE;
  huart1.AdvancedInit.AdvFeatureInit = UART_ADVFEATURE_NO_INIT;
  if (HAL_UART_Init(&huart1) != HAL_OK)
  {
    _Error_Handler(__FILE__, __LINE__);
  }

}

static void MX_DMA_Init(void)
{
  /* DMA controller clock enable */
  __HAL_RCC_DMA1_CLK_ENABLE();

}

/** Configure pins as
        * Analog
        * Input
        * Output
        * EVENT_OUT
        * EXTI
*/
static void MX_GPIO_Init(void)
{

  GPIO_InitTypeDef GPIO_InitStruct;

  /* GPIO Ports Clock Enable */
  __HAL_RCC_GPIOA_CLK_ENABLE();
  __HAL_RCC_GPIOB_CLK_ENABLE();
  __HAL_RCC_GPIOF_CLK_ENABLE();

  /*Configure GPIO pin Output Level */
  HAL_GPIO_WritePin(OC_SEL_GPIO_Port, OC_SEL_Pin, GPIO_PIN_SET);

  /*Configure GPIO pin Output Level */
  HAL_GPIO_WritePin(_3FG_HIZ_GPIO_Port, _3FG_HIZ_Pin, GPIO_PIN_RESET);

  /*Configure GPIO pin Output Level */
  HAL_GPIO_WritePin(GPIOF, OCTH_STBY2_Pin|OCTH_STBY1_Pin, GPIO_PIN_SET);

  /*Configure GPIO pins : OC_SEL_Pin _3FG_HIZ_Pin */
  GPIO_InitStruct.Pin = OC_SEL_Pin|_3FG_HIZ_Pin;
  GPIO_InitStruct.Mode = GPIO_MODE_OUTPUT_PP;
  GPIO_InitStruct.Pull = GPIO_PULLDOWN;
  GPIO_InitStruct.Speed = GPIO_SPEED_FREQ_LOW;
  HAL_GPIO_Init(GPIOA, &GPIO_InitStruct);

  /*Configure GPIO pins : OCTH_STBY2_Pin OCTH_STBY1_Pin */
  GPIO_InitStruct.Pin = OCTH_STBY2_Pin|OCTH_STBY1_Pin;
  GPIO_InitStruct.Mode = GPIO_MODE_OUTPUT_PP;
  GPIO_InitStruct.Pull = GPIO_PULLDOWN;
  GPIO_InitStruct.Speed = GPIO_SPEED_FREQ_LOW;
  HAL_GPIO_Init(GPIOF, &GPIO_InitStruct);

}

void _Error_Handler(char *file, int line)
{
  while(1)
  {
  }
}

/************************ (C) COPYRIGHT STMicroelectronics *****END OF FILE****/
